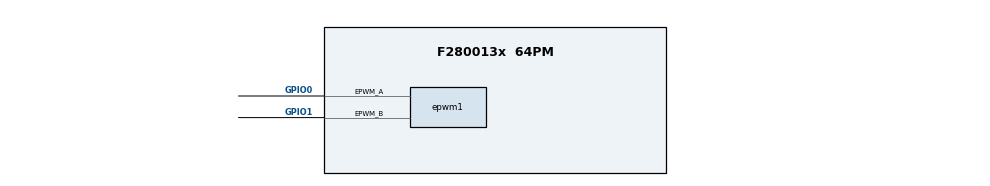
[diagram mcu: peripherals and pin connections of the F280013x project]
/**
 * @cliArgs --device "F280013x" --part "F280013x_64PM" --package "64PM" --context "system" --product "C2000WARE@6.00.00.00"
 * @versions {"tool":"1.24.0+4110"}
 */

/**
 * Import the modules used in this configuration.
 */
const adc   = scripting.addModule("/driverlib/adc.js", {}, false);
const adc1  = adc.addInstance();
const epwm  = scripting.addModule("/driverlib/epwm.js", {}, false);
const epwm1 = epwm.addInstance();

/**
 * Write custom configuration values to the imported modules.
 */
adc1.$name                   = "myADC0";
adc1.adcClockPrescaler       = "ADC_CLK_DIV_3_0";
adc1.soc0Trigger             = "ADC_TRIGGER_EPWM1_SOCA";
adc1.soc0SampleWindow        = 9;
adc1.enabledSOCs             = ["ADC_SOC_NUMBER0"];
adc1.interruptPulseMode      = "ADC_PULSE_END_OF_CONV";
adc1.enabledInts             = ["ADC_INT_NUMBER1"];
adc1.enableInterrupt1        = true;
adc1.registerInterrupts      = ["1"];
adc1.adcInt1.enableInterrupt = true;

const analog  = scripting.addModule("/driverlib/analog.js", {}, false);
const analog1 = analog.addInstance({}, false);
analog1.$name = "myANALOGPinMux0";
adc1.analog   = analog1;

epwm1.$name                                             = "myEPWM0";
epwm1.epwmTimebase_clockDiv                             = "EPWM_CLOCK_DIVIDER_4";
epwm1.epwmTimebase_hsClockDiv                           = "EPWM_HSCLOCK_DIVIDER_4";
epwm1.epwmTimebase_period                               = 2000;
epwm1.epwmTimebase_counterMode                          = "EPWM_COUNTER_MODE_UP_DOWN";
epwm1.epwmCounterCompare_cmpA                           = 1000;
epwm1.epwmEventTrigger_EPWM_SOC_A_triggerEnable         = true;
epwm1.epwmEventTrigger_EPWM_SOC_A_triggerEventPrescalar = "1";
epwm1.epwmEventTrigger_EPWM_SOC_A_triggerSource         = "EPWM_SOC_TBCTR_U_CMPA";
epwm1.epwm.$assign                                      = "EPWM1";
epwm1.epwm.epwm_aPin.$assign                            = "GPIO0";
epwm1.epwm.epwm_bPin.$assign                            = "GPIO1";

/**
 * Pinmux solution for unlocked pins/peripherals. This ensures that minor changes to the automatic solver in a future
 * version of the tool will not impact the pinmux you originally saw.  These lines can be completely deleted in order to
 * re-solve from scratch.
 */
analog1.analog.$suggestSolution                        = "ANALOG";
analog1.analog["a0/c15/cmp1_daclPin"].$suggestSolution = "A0/C15/CMP1_DACL";
analog1.analog.a1Pin.$suggestSolution                  = "A1";
analog1.analog["a10/c10, gpio230Pin"].$suggestSolution = "A10/C10, GPIO230";
analog1.analog["a11/c0Pin"].$suggestSolution           = "A11/C0";
analog1.analog["a12/c1Pin"].$suggestSolution           = "A12/C1";
analog1.analog["a15/c7Pin"].$suggestSolution           = "A15/C7";
analog1.analog["a16/c16, gpio28Pin"].$suggestSolution  = "A16/C16, GPIO28";
analog1.analog["a17/c17, gpio20Pin"].$suggestSolution  = "A17/C17, GPIO20";
analog1.analog["a18/c18, gpio21Pin"].$suggestSolution  = "A18/C18, GPIO21";
analog1.analog["a19/c19, gpio13Pin"].$suggestSolution  = "A19/C19, GPIO13";
analog1.analog["a2/c9, gpio224Pin"].$suggestSolution   = "A2/C9, GPIO224";
analog1.analog["a20/c20, gpio12Pin"].$suggestSolution  = "A20/C20, GPIO12";
analog1.analog["a3/c5, gpio242Pin"].$suggestSolution   = "A3/C5, GPIO242";
analog1.analog["a4/c14Pin"].$suggestSolution           = "A4/C14";
analog1.analog["a5/c2Pin"].$suggestSolution            = "A5/C2";
analog1.analog["a6, gpio228Pin"].$suggestSolution      = "A6, GPIO228";
analog1.analog["a7/c3Pin"].$suggestSolution            = "A7/C3";
analog1.analog["a8/c11Pin"].$suggestSolution           = "A8/C11";
analog1.analog["c4/a14Pin"].$suggestSolution           = "C4/A14";
analog1.analog["c6, gpio226Pin"].$suggestSolution      = "C6, GPIO226";
analog1.analog["c8/a9, gpio227Pin"].$suggestSolution   = "C8/A9, GPIO227";
